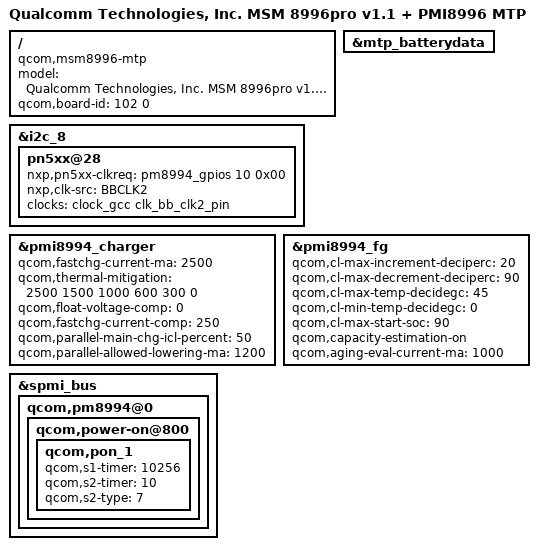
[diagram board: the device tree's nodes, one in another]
/* Copyright (c) 2016, The Linux Foundation. All rights reserved.
 *
 * This program is free software; you can redistribute it and/or modify
 * it under the terms of the GNU General Public License version 2 and
 * only version 2 as published by the Free Software Foundation.
 *
 * This program is distributed in the hope that it will be useful,
 * but WITHOUT ANY WARRANTY; without even the implied warranty of
 * MERCHANTABILITY or FITNESS FOR A PARTICULAR PURPOSE.  See the
 * GNU General Public License for more details.
 */


/dts-v1/;

#include "msm8996pro-v1.1.dtsi"
#include "msm-pmi8996.dtsi"
#include "msm8996-mtp-fujisan.dtsi"
#include "zte-msm8996pro-v1.1-pmi8996-fujisan.dtsi"

/ {
	model = "Qualcomm Technologies, Inc. MSM 8996pro v1.1 + PMI8996 MTP";
	compatible = "qcom,msm8996-mtp", "qcom,msm8996", "qcom,mtp";
	qcom,board-id = <102 0>;
};

&i2c_8 {
	pn5xx@28 {
		nxp,pn5xx-clkreq = <&pm8994_gpios 10 0x00>;
		nxp,clk-src = "BBCLK2";
		clocks = <&clock_gcc clk_bb_clk2_pin>;
		clock-names = "bb_clk2";
	};
};

&mtp_batterydata {
	#include "zte_p996a20_2930mAh.dtsi"
	#include "zte_p996a20_3180mAh.dtsi"
};

&pmi8994_charger {
	qcom,fastchg-current-ma = <2500>;
	qcom,thermal-mitigation = <2500 1500 1000 600 300 0>;
	qcom,float-voltage-comp = <0>;
	qcom,fastchg-current-comp = <250>;
	qcom,parallel-main-chg-icl-percent = <50>;
	qcom,parallel-allowed-lowering-ma = <1200>;
};

&pmi8994_fg {
	qcom,cl-max-increment-deciperc = <20>;
	qcom,cl-max-decrement-deciperc = <90>;
	qcom,cl-max-temp-decidegc = <45>;
	qcom,cl-min-temp-decidegc = <0>;
	qcom,cl-max-start-soc = <90>;
	qcom,capacity-estimation-on;
	qcom,aging-eval-current-ma = <1000>;
};

&spmi_bus {
qcom,pm8994@0 {
qcom,power-on@800 {
	qcom,pon_1 {
		qcom,s1-timer = <10256>;
		qcom,s2-timer = <10>;
		qcom,s2-type = <7>;
			};
		};
	};
};
